# APM32F40x register map
File version: 1.0
CPU: CM4 r1p0, little endian, no MPU, no FPU, 3 interrupt priority bits
Registers are 32-bit, read-write, reset 0x0 unless marked. A register's access mark holds for its fields unless they carry their own. Offsets are from the block's base; [hi:lo] are bit positions; {n}, {i} and the like mark numbered series; 'fields as' and 'values as' point back to an identical list.

## SMC — Static memory controller
Base 0xA0000000
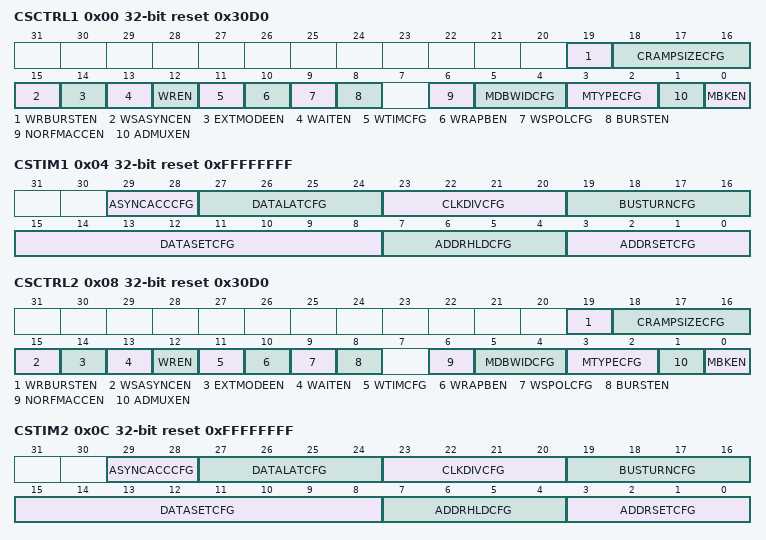
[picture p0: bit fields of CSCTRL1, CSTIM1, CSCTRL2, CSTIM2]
0x00 CSCTRL1 reset 0x30D0 — SRAM/NOR-Flash chip-select control register 1
  [19] WRBURSTEN — Write PSRAM Burst Enable
  [18:16] CRAMPSIZECFG — CRAM Page Size Configure
  [15] WSASYNCEN — Wait Signal During Asynchronous Transfers Enable
  [14] EXTMODEEN — Extended Mode Enable
  [13] WAITEN — Wait Enable
  [12] WREN — Write Memory Enable
  [11] WTIMCFG — Wait Timing Configure
  [10] WRAPBEN — Wrapped Burst Mode Enable
  [9] WSPOLCFG — Wait Signal Polarity Configure
  [8] BURSTEN — Burst Mode Enable
  [6] NORFMACCEN — NORFlash Memory Access Enable
  [5:4] MDBWIDCFG — Memory Data Bus Width Configure
  [3:2] MTYPECFG — Memory Type Configure
  [1] ADMUXEN — Address/Data Multiplexing Enable
  [0] MBKEN — Enable the Corresponding Memory Bank
0x04 CSTIM1 reset 0xFFFFFFFF — SRAM/NOR-Flash chip-select timing register 1
  [29:28] ASYNCACCCFG — Asynchronous Access Mode Configure
  [27:24] DATALATCFG — Data Latency Configure
  [23:20] CLKDIVCFG — Clock Divide Factor Configure
  [19:16] BUSTURNCFG — Bus Turnaround Phase Duration Configure
  [15:8] DATASETCFG — Data Setup Time Configure
  [7:4] ADDRHLDCFG — Address-Hold Time Configure
  [3:0] ADDRSETCFG — Address Setup Time Configure
0x08 CSCTRL2 reset 0x30D0 — SRAM/NOR-Flash chip-select control register 2
  fields as CSCTRL1
0x0C CSTIM2 reset 0xFFFFFFFF — SRAM/NOR-Flash chip-select timing register 2
  fields as CSTIM1
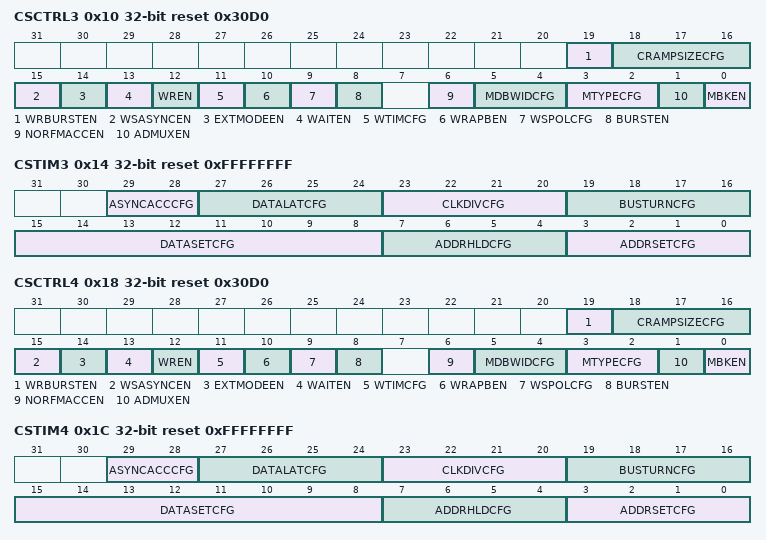
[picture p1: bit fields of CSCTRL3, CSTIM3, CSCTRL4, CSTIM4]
0x10 CSCTRL3 reset 0x30D0 — SRAM/NOR-Flash chip-select control register 3
  fields as CSCTRL1
0x14 CSTIM3 reset 0xFFFFFFFF — SRAM/NOR-Flash chip-select timing register 3
  fields as CSTIM1
0x18 CSCTRL4 reset 0x30D0 — SRAM/NOR-Flash chip-select control register 4
  fields as CSCTRL1
0x1C CSTIM4 reset 0xFFFFFFFF — SRAM/NOR-Flash chip-select timing register 4
  fields as CSTIM1
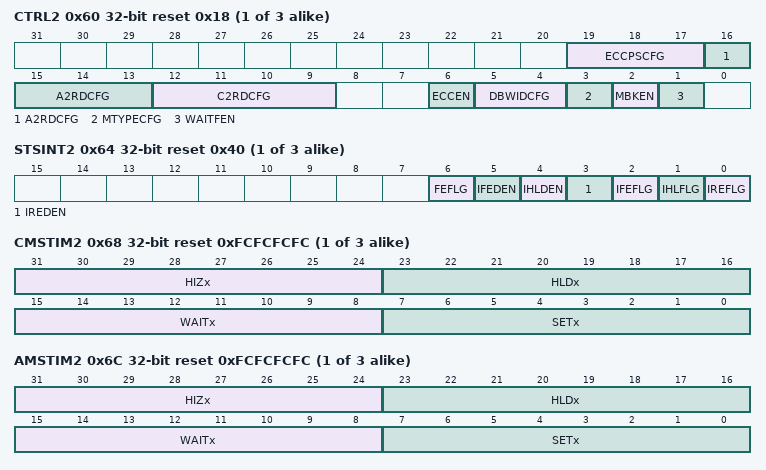
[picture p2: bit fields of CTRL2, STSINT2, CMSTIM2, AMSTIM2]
{0x20+0x20*i} CTRL{i} reset 0x18 (i=2..4) — PC Card/NAND Flash control register {i}
  [19:17] ECCPSCFG — ECC Page Size Configure
  [16:13] A2RDCFG — ALE To RE Delay Configure
  [12:9] C2RDCFG — CLE To RE Delay Configure
  [6] ECCEN — ECC Computation Logic Enable
  [5:4] DBWIDCFG — Databus Width Configure
  [3] MTYPECFG — Memory Type Configure
  [2] MBKEN — PC Card/NAND Flash Memory Bank Enable
  [1] WAITFEN — PC Card/NANDFlash Wait Feature Enable
{0x24+0x20*i} STSINT{i} access per field reset 0x40 (i=2..4) — FIFO status and interrupt register {i}
  [6] FEFLG ro — FIFO Empty Flag
  [5] IFEDEN rw — Interrupt Falling Edge Detection Enable
  [4] IHLDEN rw — Interrupt High-Level Detection Enable
  [3] IREDEN rw — Interrupt Rising Edge Detection Enable
  [2] IFEFLG rw — Interrupt Falling Edge Generate Flag
  [1] IHLFLG rw — Interrupt High-Level Generate Flag
  [0] IREFLG rw — Interrupt Rising Edge Generate Flag
{0x28+0x20*i} CMSTIM{i} reset 0xFCFCFCFC (i=2..4) — Common memory space timing register {i}
  [31:24] HIZx — Common Memory x Databus Hiz Time Configure
  [23:16] HLDx — Common Memory x Hold Time Configure
  [15:8] WAITx — Common Memory x Wait Time Configure
  [7:0] SETx — Common Memory x Setup Time Configure
{0x2C+0x20*i} AMSTIM{i} reset 0xFCFCFCFC (i=2..4) — Attribute memory space timing register {i}
  [31:24] HIZx — Attribute Memory x Databus Hiz Time Configure
  [23:16] HLDx — Attribute Memory x Hold Time Configure
  [15:8] WAITx — Attribute Memory x Wait Time Configure
  [7:0] SETx — Attribute Memory x Setup Time Configure
0x74 ECCRS2 ro — ECC result register 2
  [31:0] ECCRS — ECC result
0x94 ECCRS3 ro — ECC result register 3
  [31:0] ECCRS — ECC result
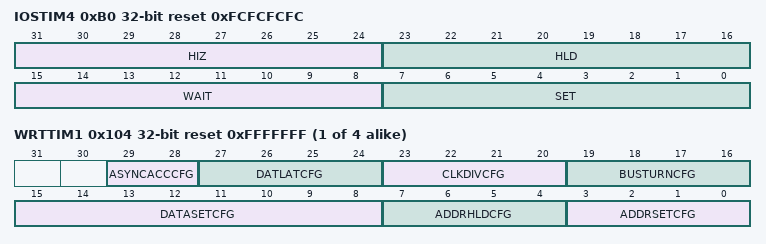
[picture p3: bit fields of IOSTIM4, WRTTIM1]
0xB0 IOSTIM4 reset 0xFCFCFCFC — I/O space timing register 4
  [31:24] HIZ — I/O x Databus Hiz Time Configure
  [23:16] HLD — I/O x Hold Time Configure
  [15:8] WAIT — I/O x Wait Time Configure
  [7:0] SET — I/O x Setup Time Configure
{0xFC+8i} WRTTIM{i} reset 0xFFFFFFF (i=1..4) — SRAM/NOR-Flash write timing registers {i}
  [29:28] ASYNCACCCFG — Asynchronous Access Mode Configure
  [27:24] DATLATCFG — Data latency Configure
  [23:20] CLKDIVCFG — Clock divide ratio (for CLK signal Configure
  [19:16] BUSTURNCFG — Bus Turnaround Phase Duration Configure
  [15:8] DATASETCFG — Data-Setup Time Configure
  [7:4] ADDRHLDCFG — Address-Hold Time Configure
  [3:0] ADDRSETCFG — Address Setup Time Configure
